# STMP3770 register map
Vendor: Freescale Semiconductor (NXP); Series: STMP37xx; File version: 1.0
CPU: other r0p0, little endian, no MPU, no FPU, 2 interrupt priority bits
Registers are 32-bit, read-write, reset 0x0 unless marked. A register's access mark holds for its fields unless they carry their own. Offsets are from the block's base; [hi:lo] are bit positions; {n}, {i} and the like mark numbered series.

## RTC — STMP3770 RTC (Real-Time Clock) 外设寄存器与位域中文描述
Base 0x8005C000
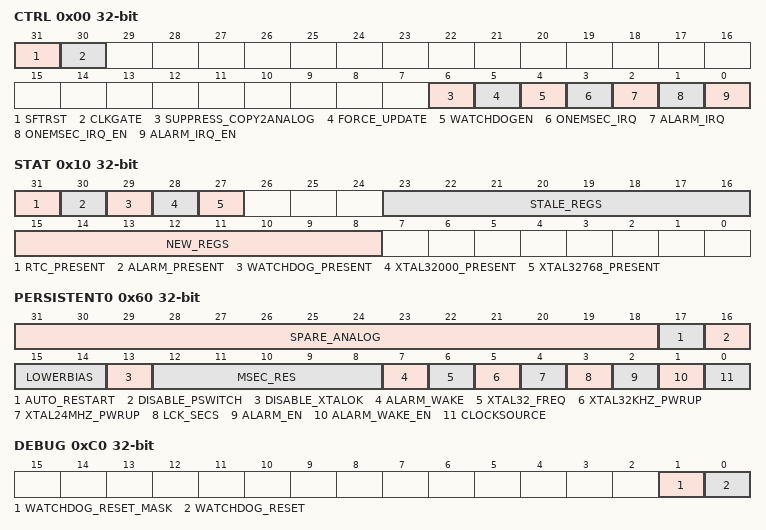
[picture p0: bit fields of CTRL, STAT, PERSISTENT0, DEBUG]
0x00 CTRL — 实时时钟控制寄存器，用于配置中断使能、看门狗、强制更新及模块时钟/复位控制。
  [31] SFTRST — 软复位，置位后对 RTC 模块执行软件复位。
  [30] CLKGATE — 时钟门控，置位后关闭 RTC 模块时钟以节能。
  [6] SUPPRESS_COPY2ANALOG — 抑制写回模拟域，置位后阻止数字域寄存器值拷贝到模拟域。
  [5] FORCE_UPDATE — 强制更新，置位后强制将数字域寄存器值写入模拟域。
  [4] WATCHDOGEN — 看门狗使能，置位后启动 WATCHDOG 计数器。
  [3] ONEMSEC_IRQ — 1毫秒中断状态标志，硬件每 1ms 置位一次，写 1 清除。
  [2] ALARM_IRQ — 闹钟中断状态标志，硬件在 ALARM 匹配时置位，写 1 清除。
  [1] ONEMSEC_IRQ_EN — 1毫秒中断使能，置位后允许每 1ms 产生一次中断。
  [0] ALARM_IRQ_EN — 闹钟中断使能，置位后允许 ALARM 匹配时产生中断。
0x10 STAT — 实时时钟状态寄存器，反映寄存器同步状态及硬件功能存在性标志。
  [31] RTC_PRESENT — RTC 模块存在标志，置位表示 RTC 硬件存在。
  [30] ALARM_PRESENT — 闹钟功能存在标志，置位表示 RTC 集成闹钟硬件。
  [29] WATCHDOG_PRESENT — 看门狗功能存在标志，置位表示 RTC 集成看门狗硬件。
  [28] XTAL32000_PRESENT — 32.000kHz 晶振存在标志，置位表示该晶振已连接并可用。
  [27] XTAL32768_PRESENT — 32.768kHz 晶振存在标志，置位表示该晶振已连接并可用。
  [23:16] STALE_REGS — 写入未完成标志，位图中置 1 的位表示对应寄存器写入模拟域尚未完成。
  [15:8] NEW_REGS — 新值待生效标志，位图中置 1 的位表示对应寄存器有新值尚未同步到模拟域。
0x20 MILLISECONDS — 实时时钟毫秒计数器，32 位自由运行毫秒计数。
  [31:0] COUNT — 毫秒计数值，32 位自由运行计数器，每 1ms 递增。
0x30 SECONDS — 实时时钟秒计数器，32 位自由运行秒计数。
  [31:0] COUNT — 秒计数值，32 位自由运行计数器，每 1 秒递增。
0x40 ALARM — 实时时钟闹钟寄存器，用于设置秒级闹钟比较值。
  [31:0] VALUE — 闹钟比较值，当 SECONDS.COUNT 等于该值时触发闹钟事件。
0x50 WATCHDOG — 看门狗定时器寄存器，用于配置看门狗倒计数初值。
  [31:0] COUNT — 看门狗倒计数值，写入后递减，减至 0 时触发看门狗复位。
0x60 PERSISTENT0 — 掉电保持状态寄存器 0，保存系统级持久控制位，掉电后由备用电源维持。
  [31:18] SPARE_ANALOG — 模拟域备用位，14 位保留给模拟电路使用的备用配置字段。
  [17] AUTO_RESTART — 自动重启使能，置位后系统在特定条件下自动重新启动。
  [16] DISABLE_PSWITCH — 禁用 PSWITCH 功能，置位后关闭电源开关检测。
  [15:14] LOWERBIAS — 降低偏置电流配置，2 位字段用于调节模拟偏置电流以降低功耗。
  [13] DISABLE_XTALOK — 禁用 XTAL 正常指示，置位后关闭晶振起振 OK 检测。
  [12:8] MSEC_RES — 毫秒分辨率配置，5 位字段用于设置毫秒计数器的分辨率。
  [7] ALARM_WAKE — 闹钟唤醒标志，置位表示系统由闹钟事件唤醒。
  [6] XTAL32_FREQ — 32kHz 晶振频率选择，0 表示 32.768kHz，1 表示 32.000kHz。
  [5] XTAL32KHZ_PWRUP — 32kHz 晶振上电控制，置位后给 32kHz 晶振电路上电。
  [4] XTAL24MHZ_PWRUP — 24MHz 晶振上电控制，置位后给 24MHz 晶振电路上电。
  [3] LCK_SECS — 秒计数器锁定，置位后锁定 SECONDS 寄存器防止误写。
  [2] ALARM_EN — 闹钟功能使能，置位后启用 RTC 闹钟比较功能。
  [1] ALARM_WAKE_EN — 闹钟唤醒使能，置位后允许闹钟事件将系统从低功耗状态唤醒。
  [0] CLOCKSOURCE — RTC 时钟源选择，0 表示 32.768kHz 晶振，1 表示 32.000kHz 晶振。
0x70 PERSISTENT1 — 掉电保持状态寄存器 1，32 位通用持久存储，可用于保存系统标志。
  [31:0] GENERAL — 通用 32 位持久数据，掉电保持，可存储系统标志(如 USB 启动模式、OTG 角色等)。
    0x1000=ENUMERATE_500MA_TWICE; 0x800=USB_BOOT_PLAYER_MODE; 0x400=SKIP_CHECKDISK; 0x200=USB_LOW_POWER_MODE; 0x100=OTG_HNP_BIT; 128=OTG_ATL_ROLE_BIT
{0x60+0x10*i} PERSISTENT{i} (i=2..5) — 掉电保持状态寄存器 {i}，32 位通用持久存储。
  [31:0] GENERAL — 通用 32 位持久数据，掉电保持，由软件自由使用。
0xC0 DEBUG ro — 实时时钟调试寄存器，用于控制看门狗复位行为。
  [1] WATCHDOG_RESET_MASK — 看门狗复位屏蔽，置位后屏蔽看门狗产生的系统复位。
  [0] WATCHDOG_RESET — 看门狗复位标志，置位表示看门狗已触发复位。
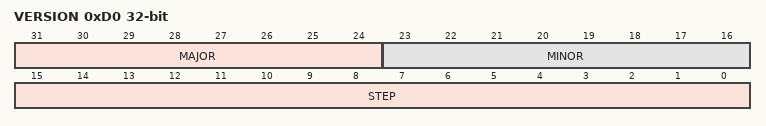
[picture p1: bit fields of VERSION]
0xD0 VERSION ro — 实时时钟版本寄存器，反映 RTC 模块的硬件版本信息。
  [31:24] MAJOR — 主版本号，8 位字段表示当前硬件的主要版本。
  [23:16] MINOR — 次版本号，8 位字段表示当前硬件的次要版本。
  [15:0] STEP — 步进版本号，16 位字段表示当前硬件的步进版本。

## PWM — 脉宽调制控制器(多通道 PWM 输出,可用于背光/蜂鸣等)
Base 0x80064000
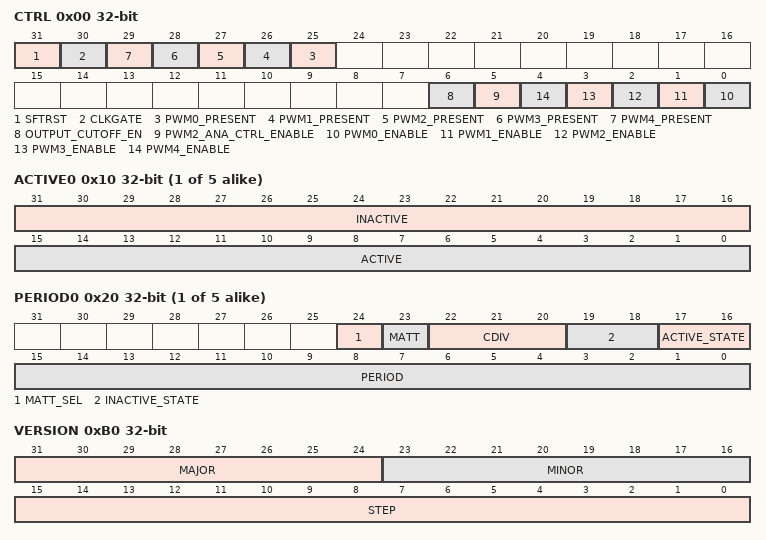
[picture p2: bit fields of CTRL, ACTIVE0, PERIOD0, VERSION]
0x00 CTRL — PWM Control and Status Register
  [31] SFTRST — Bit 31. Must be cleared to 0 for normal operation. When set to 1, forces a block-wide reset.
  [30] CLKGATE — Bit 30. Must be cleared to 0 for normal operation. When set to 1, gates off the clocks to the block.
  [n+25] PWM{n}_PRESENT (n=0..4) — Bit {n+25}. Read-only. 0 = PWM{n} is not present in this product.
  [6] OUTPUT_CUTOFF_EN — 输出截止使能，超出有效周期后强制输出无效态。
  [5] PWM2_ANA_CTRL_ENABLE — Bit 5. Setting to 1 enables PWM Channel 2 output to be enabled by analog circuitry outside this block.
  [n] PWM{n}_ENABLE (n=0..4) — Bit {n}. Enables PWM channel {n} to begin cycling when set to 1.
{0x10+0x20*i} ACTIVE{i} (i=0..4)
  [31:16] INACTIVE — PWM通道无效周期计数值（以分频后晶振周期为单位）。
  [15:0] ACTIVE — PWM通道有效周期计数值（以分频后晶振周期为单位）。
{0x20+0x20*i} PERIOD{i} (i=0..4)
  [24] MATT_SEL — 多芯片连接模式选择。
  [23] MATT — 多芯片连接模式，将24MHz晶振时钟输出到PWM引脚。
  [22:20] CDIV — 时钟分频比选择：1/2/4/8/16/64/256/1024。
    0=DIV_1; 1=DIV_2; 2=DIV_4; 3=DIV_8; 4=DIV_16; 5=DIV_64; 6=DIV_256; 7=DIV_1024
  [19:18] INACTIVE_STATE — 无效状态电平选择：0=高阻，2=低电平，3=高电平。
    0=HI_Z; 2=_0; 3=_1
  [17:16] ACTIVE_STATE — 有效状态电平选择：0=高阻，2=低电平，3=高电平。
    0=HI_Z; 2=_0; 3=_1
  [15:0] PERIOD — PWM通道周期计数值（周期 = PERIOD+1 个分频时钟）。
0xB0 VERSION ro — PWM Version Register
  [31:24] MAJOR — Bits 31:24. Read-only. Fixed value reflecting the MAJOR field of the RTL version. Reset: 0x01.
  [23:16] MINOR — Bits 23:16. Read-only. Fixed value reflecting the MINOR field of the RTL version. Reset: 0x01.
  [15:0] STEP — Bits 15:0. Read-only. Fixed value reflecting the stepping of the RTL version. Reset: 0x0000.

## TIMROT — STMP3770 TIMROT 外设：定时器与旋钮解码器。包含 4 个通用定时器（Timer0~3）和 1 个旋钮解码器，支持 PWM、晶振及旋钮输入等多种时钟源，可配置预分频、自动重载、中断等功能。ROTCTRL 控制旋钮解码器输入源、极性、过采样率及分频等；ROTCOUNT 保存旋钮旋转产生的计数值。各定时器通过 TIMCTRLn/TIMCOUNTn 寄存器组独立控制与计数。
Base 0x80068000
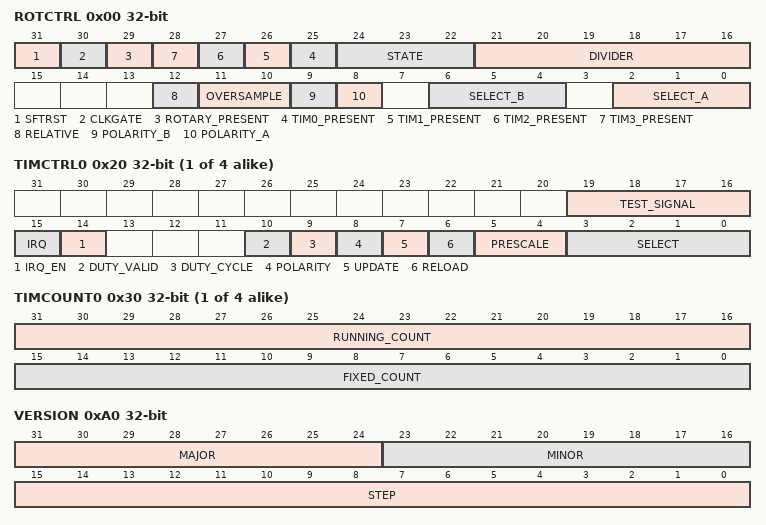
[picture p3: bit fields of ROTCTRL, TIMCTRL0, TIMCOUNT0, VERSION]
0x00 ROTCTRL — 旋钮解码器控制寄存器，配置输入源选择、极性、过采样率、相对模式、分频系数，以及各定时器/旋钮存在性标志、时钟门控和软复位。
  [31] SFTRST — 软复位控制位，置位时对整个 TIMROT 模块执行软件复位。
  [30] CLKGATE — 时钟门控控制位，用于控制 TIMROT 模块时钟以节省功耗。
  [29] ROTARY_PRESENT — 旋钮解码器存在性标志，只读，1 表示该模块存在。
  [n+25] TIM{n}_PRESENT (n=0..3) — Timer{n} 存在性标志，只读，1 表示该定时器存在。
  [24:22] STATE — 旋钮解码器当前状态，3 位只读状态值。
  [21:16] DIVIDER — 旋钮输入时钟分频系数，6 位无符号值。
  [12] RELATIVE — 旋钮相对模式使能，置位后计数器按相对变化量累加或递减。
  [11:10] OVERSAMPLE — 旋钮过采样率选择：8X/4X/2X/1X。
    0=_8X; 1=_4X; 2=_2X; 3=_1X
  [9] POLARITY_B — 旋钮 B 输入极性控制位。
  [8] POLARITY_A — 旋钮 A 输入极性控制位。
  [6:4] SELECT_B — 旋钮 B 输入源选择：NEVER_TICK=不选；PWM0~4=对应 PWM 通道；ROTARYA/B=旋钮 A/B 输入。
    0=NEVER_TICK; {v}=PWM{v-1} (v=1..5); 6=ROTARYA; 7=ROTARYB
  [2:0] SELECT_A — 旋钮 A 输入源选择：NEVER_TICK=不选；PWM0~4=对应 PWM 通道；ROTARYA/B=旋钮 A/B 输入。
    0=NEVER_TICK; {v}=PWM{v-1} (v=1..5); 6=ROTARYA; 7=ROTARYB
0x10 ROTCOUNT — 旋钮解码器上下计数寄存器，保存旋钮旋转产生的计数值。
  [15:0] UPDOWN — 旋钮上下计数值，16 位，反映旋钮旋转的方向与幅度。
{0x20+0x20*i} TIMCTRL{i} (i=0..3) — 定时器控制寄存器（数组，4 个实例），配置时钟源、预分频、自动重载、更新触发、极性、中断使能及中断状态。
  [19:16] TEST_SIGNAL — 被测信号源选择(仅TIMCTRL3占空比模式)，枚举值与SELECT字段相同。
  [15] IRQ — 定时器中断状态标志，计数到零时置位。
  [14] IRQ_EN — 定时器中断使能控制位，置位时允许计数到零产生中断。
  [10] DUTY_VALID ro — 占空比数据有效标志(仅TIMCTRL3)，只读，硬件置位表示TIMCOUNT3中占空比数据有效。
  [9] DUTY_CYCLE — 占空比测量模式使能(仅TIMCTRL3)，置位时进入占空比测量模式，TIMCOUNT3记录高电平宽度。
  [8] POLARITY — 定时器极性控制位。
  [7] UPDATE — 更新控制位，置位后刷新计数值并使能计数器。
  [6] RELOAD — 自动重载使能，计数到零后自动从 FIXED_COUNT 重新加载并继续计数。
  [5:4] PRESCALE — 定时器预分频选择：DIV_BY_1=1 分频；DIV_BY_2=2 分频；DIV_BY_4=4 分频；DIV_BY_8=8 分频。
    0=DIV_BY_1; 1=DIV_BY_2; 2=DIV_BY_4; 3=DIV_BY_8
  [3:0] SELECT — 定时器时钟源选择：NEVER_TICK=不选；PWM0~4=对应 PWM 通道；ROTARYA/B=旋钮输入；32KHZ_XTAL/8KHZ_XTAL/4KHZ_XTAL/1KHZ_XTAL=对应晶振；TICK_ALWAYS=始终滴答。
    0=NEVER_TICK; {v}=PWM{v-1} (v=1..5); 6=ROTARYA; 7=ROTARYB; 8=_32KHZ_XTAL; 9=_8KHZ_XTAL; 10=_4KHZ_XTAL; 11=_1KHZ_XTAL; 12=TICK_ALWAYS
{0x30+0x20*i} TIMCOUNT{i} (i=0..3) — 定时器计数寄存器（数组，4 个实例），包含重载初值与当前递减计数值。
  [31:16] RUNNING_COUNT — 定时器当前递减计数值，16 位只读，计数过程中实时递减。
  [15:0] FIXED_COUNT — 定时器重载初值，计数器归零时从此值重新加载（需 RELOAD 使能）。
0xA0 VERSION ro — TIMROT 版本寄存器，保存模块的步进、次要和主要版本号。
  [31:24] MAJOR — 主要版本号，8 位。
  [23:16] MINOR — 次要版本号，8 位。
  [15:0] STEP — 步进版本号，16 位。
